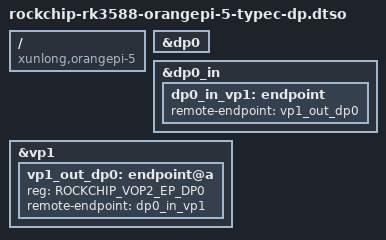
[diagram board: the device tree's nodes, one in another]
// SPDX-License-Identifier: (GPL-2.0+ OR MIT)
/*
 * Orange Pi 5 / 5B -- DisplayPort over the USB-C port.
 *
 * The Type-C side is already complete in mainline: the fusb302 negotiates
 * the DisplayPort altmode and the USBDP combo PHY's typec mux re-routes its
 * lanes to DP (rk_udphy_typec_mux_set(), TYPEC_DP_STATE_C/D/E). What is
 * missing is a DP controller behind it -- rk3588s-orangepi-5.dtsi never
 * enables &dp0, so it keeps the "disabled" it inherits from rk3588-base.dtsi
 * and never probes. The PHY happily switches its lanes to DP for a sink that
 * nothing drives.
 *
 * The vendor 6.1 kernel enables it straight from the board dtsi, routed to
 * VP1:
 *
 *	&dp0        { status = "okay"; };
 *	&dp0_in_vp1 { status = "okay"; };
 *	&dp0_in_vp2 { status = "disabled"; };
 *
 * Those dp0_in_vp* labels are a vendor invention and do not exist here.
 * Mainline declares dp0_in/dp0_out as bare ports and leaves the endpoints to
 * the board, which is what this overlay adds -- same shape
 * rk3588s-coolpi-4b.dts uses for its mini-DP port.
 *
 * VP1 because HDMI0 already drives VP0. DP0's input is a mux
 * (RK3588_SYS_DSP_INFACE_EN_DP0_MUX is 2 bits wide) so any of VP0-VP3 would
 * do, but VP1 is what the vendor kernel picked.
 *
 * No dp0_out endpoint: dw_dp_bind() attaches its bridge with
 * DRM_BRIDGE_ATTACH_NO_CONNECTOR and that bridge carries DETECT|EDID|HPD
 * itself, so the encoder gets its connector from the bridge chain. A Type-C
 * sink has no connector node of its own to point at.
 *
 * Note this is *not* for the 5 Pro. That board includes the same dtsi but
 * sends DP0 to its DP-to-HDMI bridge through its own dp0_in_vp2 endpoint,
 * and a port only carries one.
 */

/dts-v1/;
/plugin/;

#include <dt-bindings/soc/rockchip,vop2.h>

/ {
	compatible = "xunlong,orangepi-5", "xunlong,orangepi-5b", "rockchip,rk3588s";
};

&dp0 {
	status = "okay";
};

&dp0_in {
	dp0_in_vp1: endpoint {
		remote-endpoint = <&vp1_out_dp0>;
	};
};

&vp1 {
	/* Restated because dtc checks each fragment on its own, without the
	 * base tree's properties to lean on. */
	#address-cells = <1>;
	#size-cells = <0>;

	/* @a, not @ROCKCHIP_VOP2_EP_DP0: unit addresses are read as hex, so the
	 * macro would expand to endpoint@10, i.e. 16, and mismatch reg. The
	 * other EP_* macros are single-digit and hide this.
	 */
	vp1_out_dp0: endpoint@a {
		reg = <ROCKCHIP_VOP2_EP_DP0>;
		remote-endpoint = <&dp0_in_vp1>;
	};
};
